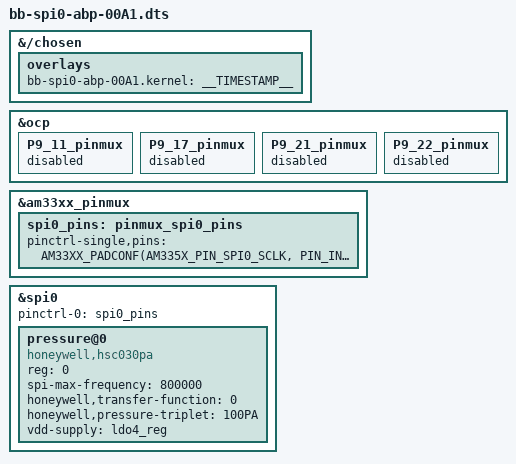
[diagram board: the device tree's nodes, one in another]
// SPDX-License-Identifier: GPL-2.0-only

/dts-v1/;
/plugin/;

#include <dt-bindings/gpio/gpio.h>
#include <dt-bindings/pinctrl/am33xx.h>

/*
 * Helper to show loaded overlays under: /proc/device-tree/chosen/overlays/
 */
&{/chosen} {
	overlays {
		bb-spi0-abp-00A1.kernel = __TIMESTAMP__;
	};
};

/*
 * Free up the pins used by the cape from the pinmux helpers.
 */
&ocp {
	P9_11_pinmux { status = "disabled"; };	/* P9_11 honeywell chip CS pin */
	P9_17_pinmux { status = "disabled"; };	/* P9_17 (A16) spi0_cs0.spi0_cs0 */
	P9_21_pinmux { status = "disabled"; };	/* P9_21 (B17) spi0_d0.spi0_d0 */
	P9_22_pinmux { status = "disabled"; };	/* P9_22 (A17) spi0_sclk.spi0_sclk */
};

&am33xx_pinmux {
	spi0_pins: pinmux_spi0_pins {
		pinctrl-single,pins = <
			AM33XX_PADCONF(AM335X_PIN_SPI0_SCLK, PIN_INPUT, MUX_MODE0)	/* P9_22 (A17) spi0_sclk.spi0_sclk */
			AM33XX_PADCONF(AM335X_PIN_SPI0_D0, PIN_INPUT, MUX_MODE0)	/* P9_21 (B17) spi0_d0.spi0_d0 */
			AM33XX_PADCONF(AM335X_PIN_SPI0_CS0, PIN_INPUT, MUX_MODE0)	/* P9_17 (A16) spi0_cs0.spi0_cs0 */
		>;
	};
};

&spi0 {
	#address-cells = <1>;
	#size-cells = <0>;

	status = "okay";
	pinctrl-names = "default";
	pinctrl-0 = <&spi0_pins>;

/*
	channel@0{
		status = "disabled";
		reg = <0>;
	};
*/

	pressure@0{
		compatible = "honeywell,hsc030pa";
		reg = <0>;
		spi-max-frequency = <800000>;

		honeywell,transfer-function = <0>;
		honeywell,pressure-triplet = "100PA";

		// in case of a custom range, use NA as pressure-triplet
		// and populate pmin-pascal and pmax-pascal
		// with the range limits converted into pascals
		//honeywell,pressure-triplet = "NA";
		//honeywell,pmin-pascal = <0>;
		//honeywell,pmax-pascal = <206850>;

		vdd-supply = <&ldo4_reg>;
		status = "okay";
	};
};
